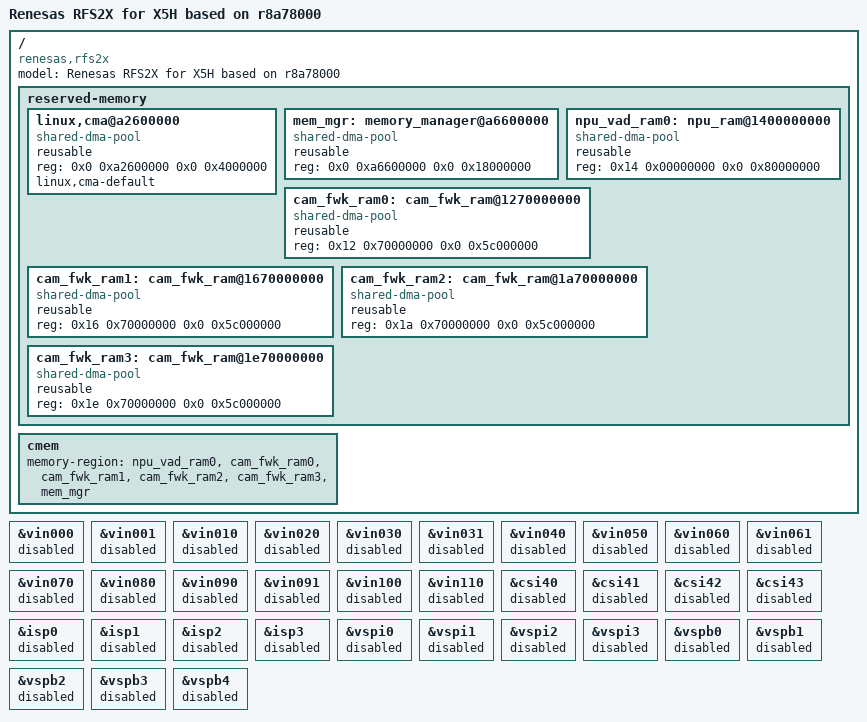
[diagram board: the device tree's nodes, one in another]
// SPDX-License-Identifier: GPL-2.0
/*
 * Device Tree Source for the RFS2X board based on R8A78000
 *
 * Copyright (C) 2025 Renesas Electronics Corp.
 */

/dts-v1/;
#include "r8a78000-uio.dtsi"
#include "r8a78000-rfs2x-common.dtsi"

/ {
	model = "Renesas RFS2X for X5H based on r8a78000";
	compatible = "renesas,rfs2x", "renesas,r8a78000";

	reserved-memory {
		#address-cells = <2>;
		#size-cells = <2>;
		ranges;

		/delete-node/ linux,cma@a2600000;

		linux,cma@a2600000 {
			compatible = "shared-dma-pool";
			reusable;
			reg = <0x0 0xa2600000 0x0 0x4000000>;
			linux,cma-default;
		};

		mem_mgr: memory_manager@a6600000 {
			compatible = "shared-dma-pool";
			reusable;
			reg = <0x0 0xa6600000 0x0 0x18000000>;
		};

		npu_vad_ram0: npu_ram@1400000000 {
			compatible = "shared-dma-pool";
			reusable;
			reg = <0x14 0x00000000 0x0 0x80000000>;
		};

		cam_fwk_ram0: cam_fwk_ram@1270000000 {
			compatible = "shared-dma-pool";
			reusable;
			reg = <0x12 0x70000000 0x0 0x5c000000>;
		};

		cam_fwk_ram1: cam_fwk_ram@1670000000 {
			compatible = "shared-dma-pool";
			reusable;
			reg = <0x16 0x70000000 0x0 0x5c000000>;
		};

		cam_fwk_ram2: cam_fwk_ram@1a70000000 {
			compatible = "shared-dma-pool";
			reusable;
			reg = <0x1a 0x70000000 0x0 0x5c000000>;
		};

		cam_fwk_ram3: cam_fwk_ram@1e70000000 {
			compatible = "shared-dma-pool";
			reusable;
			reg = <0x1e 0x70000000 0x0 0x5c000000>;
		};
	};

	cmem {
		memory-region = <&npu_vad_ram0>,
				<&cam_fwk_ram0>, <&cam_fwk_ram1>,
				<&cam_fwk_ram2>, <&cam_fwk_ram3>,
				<&mem_mgr>;
	};
};

&vin000 {
	status = "enabled";
};

&vin001 {
	status = "enabled";
};

&vin010 {
	status = "enabled";
};

&vin020 {
	status = "enabled";
};

&vin030 {
	status = "enabled";
};

&vin031 {
	status = "enabled";
};

&vin040 {
	status = "enabled";
};

&vin050 {
	status = "enabled";
};

&vin060 {
	status = "enabled";
};

&vin061 {
	status = "enabled";
};

&vin070 {
	status = "enabled";
};

&vin080 {
	status = "enabled";
};

&vin090 {
	status = "enabled";
};

&vin091 {
	status = "enabled";
};

&vin100 {
	status = "enabled";
};

&vin110 {
	status = "enabled";
};

&csi40 {
	status = "enabled";
};

&csi41 {
	status = "enabled";
};

&csi42 {
	status = "enabled";
};

&csi43 {
	status = "enabled";
};

&isp0 {
	status = "enabled";
};

&isp1 {
	status = "enabled";
};

&isp2 {
	status = "enabled";
};

&isp3 {
	status = "enabled";
};

&vspi0 {
	status = "disabled";
};

&vspi1 {
	status = "disabled";
};

&vspi2 {
	status = "disabled";
};

&vspi3 {
	status = "disabled";
};

&vspb0 {
	status = "disabled";
};

&vspb1 {
	status = "disabled";
};

&vspb2 {
	status = "disabled";
};

&vspb3 {
	status = "disabled";
};

&vspb4 {
	status = "disabled";
};
